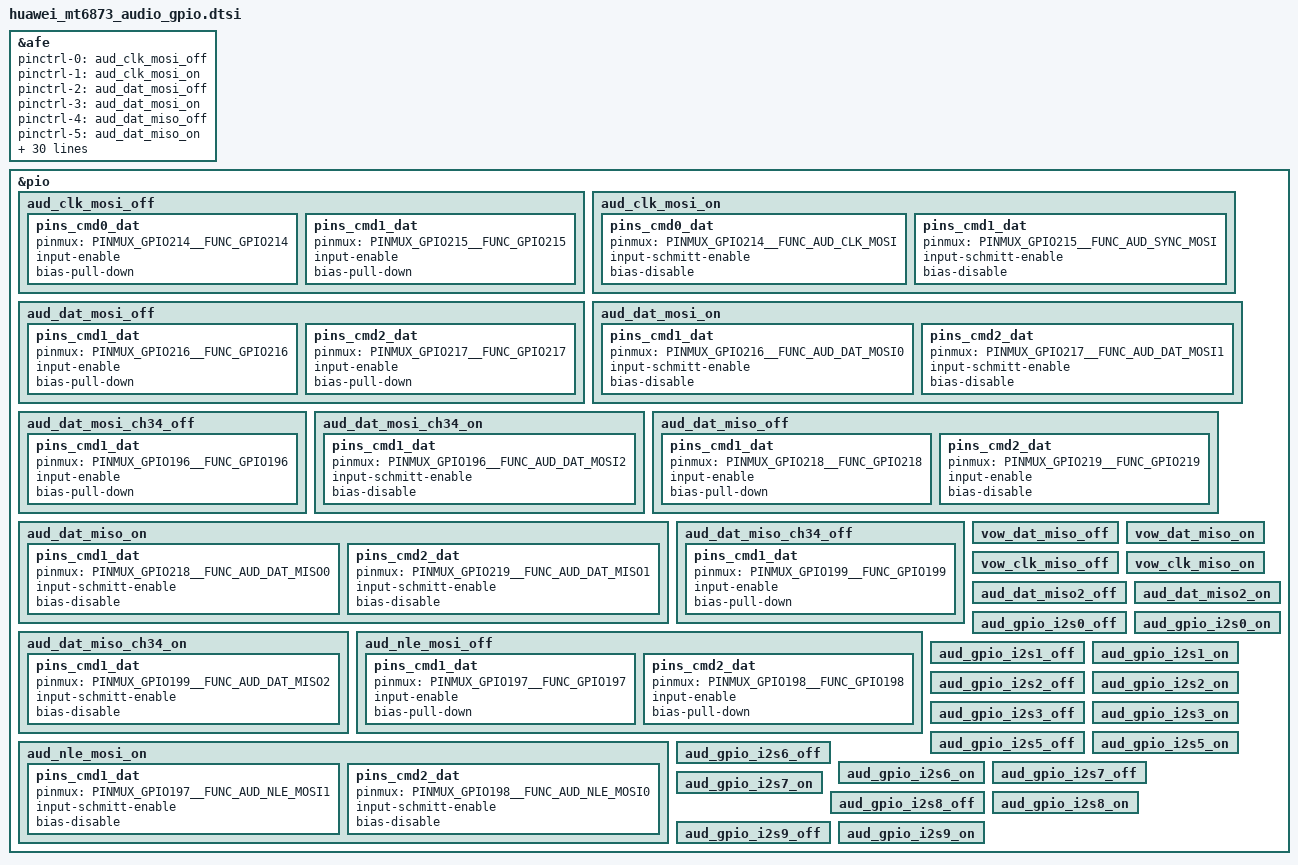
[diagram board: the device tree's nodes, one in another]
/* AUDIO GPIO standardization */
&afe {
	pinctrl-names = "aud_clk_mosi_off",
					"aud_clk_mosi_on",
					"aud_dat_mosi_off",
					"aud_dat_mosi_on",
					"aud_dat_miso_off",
					"aud_dat_miso_on",
					"vow_dat_miso_off",
					"vow_dat_miso_on",
					"vow_clk_miso_off",
					"vow_clk_miso_on",
					"aud_nle_mosi_off",
					"aud_nle_mosi_on",
					"aud_dat_miso2_off",
					"aud_dat_miso2_on",
					"aud_gpio_i2s0_off",
					"aud_gpio_i2s0_on",
					"aud_gpio_i2s1_off",
					"aud_gpio_i2s1_on",
					"aud_gpio_i2s2_off",
					"aud_gpio_i2s2_on",
					"aud_gpio_i2s3_off",
					"aud_gpio_i2s3_on",
					"aud_gpio_i2s5_off",
					"aud_gpio_i2s5_on",
					"aud_gpio_i2s6_off",
					"aud_gpio_i2s6_on",
					"aud_gpio_i2s7_off",
					"aud_gpio_i2s7_on",
					"aud_gpio_i2s8_off",
					"aud_gpio_i2s8_on",
					"aud_gpio_i2s9_off",
					"aud_gpio_i2s9_on",
					"aud_dat_mosi_ch34_off",
					"aud_dat_mosi_ch34_on",
					"aud_dat_miso_ch34_off",
					"aud_dat_miso_ch34_on";
	pinctrl-0 = <&aud_clk_mosi_off>;
	pinctrl-1 = <&aud_clk_mosi_on>;
	pinctrl-2 = <&aud_dat_mosi_off>;
	pinctrl-3 = <&aud_dat_mosi_on>;
	pinctrl-4 = <&aud_dat_miso_off>;
	pinctrl-5 = <&aud_dat_miso_on>;
	pinctrl-6 = <&vow_dat_miso_off>;
	pinctrl-7 = <&vow_dat_miso_on>;
	pinctrl-8 = <&vow_clk_miso_off>;
	pinctrl-9 = <&vow_clk_miso_on>;
	pinctrl-10 = <&aud_nle_mosi_off>;
	pinctrl-11 = <&aud_nle_mosi_on>;
	pinctrl-12 = <&aud_dat_miso2_off>;
	pinctrl-13 = <&aud_dat_miso2_on>;
	pinctrl-14 = <&aud_gpio_i2s0_off>;
	pinctrl-15 = <&aud_gpio_i2s0_on>;
	pinctrl-16 = <&aud_gpio_i2s1_off>;
	pinctrl-17 = <&aud_gpio_i2s1_on>;
	pinctrl-18 = <&aud_gpio_i2s2_off>;
	pinctrl-19 = <&aud_gpio_i2s2_on>;
	pinctrl-20 = <&aud_gpio_i2s3_off>;
	pinctrl-21 = <&aud_gpio_i2s3_on>;
	pinctrl-22 = <&aud_gpio_i2s5_off>;
	pinctrl-23 = <&aud_gpio_i2s5_on>;
	pinctrl-24 = <&aud_gpio_i2s6_off>;
	pinctrl-25 = <&aud_gpio_i2s6_on>;
	pinctrl-26 = <&aud_gpio_i2s7_off>;
	pinctrl-27 = <&aud_gpio_i2s7_on>;
	pinctrl-28 = <&aud_gpio_i2s8_off>;
	pinctrl-29 = <&aud_gpio_i2s8_on>;
	pinctrl-30 = <&aud_gpio_i2s9_off>;
	pinctrl-31 = <&aud_gpio_i2s9_on>;
	pinctrl-32 = <&aud_dat_mosi_ch34_off>;
	pinctrl-33 = <&aud_dat_mosi_ch34_on>;
	pinctrl-34 = <&aud_dat_miso_ch34_off>;
	pinctrl-35 = <&aud_dat_miso_ch34_on>;
	status = "okay";
};

&pio {
	aud_clk_mosi_off: aud_clk_mosi_off {
		pins_cmd0_dat {
			pinmux = <PINMUX_GPIO214__FUNC_GPIO214>;
			input-enable;
			bias-pull-down;
		};
		pins_cmd1_dat {
			pinmux = <PINMUX_GPIO215__FUNC_GPIO215>;
			input-enable;
			bias-pull-down;
		};
	};
	aud_clk_mosi_on: aud_clk_mosi_on {
		pins_cmd0_dat {
			pinmux = <PINMUX_GPIO214__FUNC_AUD_CLK_MOSI>;
			input-schmitt-enable;
			bias-disable;
		};
		pins_cmd1_dat {
			pinmux = <PINMUX_GPIO215__FUNC_AUD_SYNC_MOSI>;
			input-schmitt-enable;
			bias-disable;
		};
	};
	aud_dat_mosi_off: aud_dat_mosi_off {
		pins_cmd1_dat {
			pinmux = <PINMUX_GPIO216__FUNC_GPIO216>;
			input-enable;
			bias-pull-down;
		};
		pins_cmd2_dat {
			pinmux = <PINMUX_GPIO217__FUNC_GPIO217>;
			input-enable;
			bias-pull-down;
		};
	};
	aud_dat_mosi_on: aud_dat_mosi_on {
		pins_cmd1_dat {
			pinmux = <PINMUX_GPIO216__FUNC_AUD_DAT_MOSI0>;
			input-schmitt-enable;
			bias-disable;
		};
		pins_cmd2_dat {
			pinmux = <PINMUX_GPIO217__FUNC_AUD_DAT_MOSI1>;
			input-schmitt-enable;
			bias-disable;
		};
	};
	aud_dat_mosi_ch34_off: aud_dat_mosi_ch34_off {
		pins_cmd1_dat {
			pinmux = <PINMUX_GPIO196__FUNC_GPIO196>;
			input-enable;
			bias-pull-down;
		};
	};
	aud_dat_mosi_ch34_on: aud_dat_mosi_ch34_on {
		pins_cmd1_dat {
			pinmux = <PINMUX_GPIO196__FUNC_AUD_DAT_MOSI2>;
			input-schmitt-enable;
			bias-disable;
		};
	};
	aud_dat_miso_off: aud_dat_miso_off {
		pins_cmd1_dat {
			pinmux = <PINMUX_GPIO218__FUNC_GPIO218>;
			input-enable;
			bias-pull-down;
		};
		pins_cmd2_dat {
			pinmux = <PINMUX_GPIO219__FUNC_GPIO219>;
			input-enable;
			bias-disable;
		};
	};
	aud_dat_miso_on: aud_dat_miso_on {
		pins_cmd1_dat {
			pinmux = <PINMUX_GPIO218__FUNC_AUD_DAT_MISO0>;
			input-schmitt-enable;
			bias-disable;
		};
		pins_cmd2_dat {
			pinmux = <PINMUX_GPIO219__FUNC_AUD_DAT_MISO1>;
			input-schmitt-enable;
			bias-disable;
		};
	};
	aud_dat_miso_ch34_off: aud_dat_miso_ch34_off {
		pins_cmd1_dat {
			pinmux = <PINMUX_GPIO199__FUNC_GPIO199>;
			input-enable;
			bias-pull-down;
		};
	};
	aud_dat_miso_ch34_on: aud_dat_miso_ch34_on {
		pins_cmd1_dat {
			pinmux = <PINMUX_GPIO199__FUNC_AUD_DAT_MISO2>;
			input-schmitt-enable;
			bias-disable;
		};
	};
	vow_dat_miso_off: vow_dat_miso_off {
	};
	vow_dat_miso_on: vow_dat_miso_on {
	};
	vow_clk_miso_off: vow_clk_miso_off {
	};
	vow_clk_miso_on: vow_clk_miso_on {
	};
	aud_nle_mosi_off: aud_nle_mosi_off {
		pins_cmd1_dat {
			pinmux = <PINMUX_GPIO197__FUNC_GPIO197>;
			input-enable;
			bias-pull-down;
		};
		pins_cmd2_dat {
			pinmux = <PINMUX_GPIO198__FUNC_GPIO198>;
			input-enable;
			bias-pull-down;
		};
	};
	aud_nle_mosi_on: aud_nle_mosi_on {
		pins_cmd1_dat {
			pinmux = <PINMUX_GPIO197__FUNC_AUD_NLE_MOSI1>;
			input-schmitt-enable;
			bias-disable;
		};
		pins_cmd2_dat {
			pinmux = <PINMUX_GPIO198__FUNC_AUD_NLE_MOSI0>;
			input-schmitt-enable;
			bias-disable;
		};
	};
	aud_dat_miso2_off: aud_dat_miso2_off {
	};
	aud_dat_miso2_on: aud_dat_miso2_on {
	};
	aud_gpio_i2s0_off: aud_gpio_i2s0_off {
	};
	aud_gpio_i2s0_on: aud_gpio_i2s0_on {
	};
	aud_gpio_i2s1_off: aud_gpio_i2s1_off {
	};
	aud_gpio_i2s1_on: aud_gpio_i2s1_on {
	};
	aud_gpio_i2s2_off: aud_gpio_i2s2_off {
	};
	aud_gpio_i2s2_on: aud_gpio_i2s2_on {
	};
	aud_gpio_i2s3_off: aud_gpio_i2s3_off {
	};
	aud_gpio_i2s3_on: aud_gpio_i2s3_on {
	};
	aud_gpio_i2s5_off: aud_gpio_i2s5_off {
	};
	aud_gpio_i2s5_on: aud_gpio_i2s5_on {
	};
	aud_gpio_i2s6_off: aud_gpio_i2s6_off {
	};
	aud_gpio_i2s6_on: aud_gpio_i2s6_on {
	};
	aud_gpio_i2s7_off: aud_gpio_i2s7_off {
	};
	aud_gpio_i2s7_on: aud_gpio_i2s7_on {
	};
	aud_gpio_i2s8_off: aud_gpio_i2s8_off {
	};
	aud_gpio_i2s8_on: aud_gpio_i2s8_on {
	};
	aud_gpio_i2s9_off: aud_gpio_i2s9_off {
	};
	aud_gpio_i2s9_on: aud_gpio_i2s9_on {
	};
};
/* AUDIO GPIO END */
